# STM32F103ZET7 register map
File version: 1.0
Registers are 32-bit, access not given, reset 0x0 unless marked. A register's access mark holds for its fields unless they carry their own. Offsets are from the block's base; [hi:lo] are bit positions; {n}, {i} and the like mark numbered series; 'fields as' and 'values as' point back to an identical list.

## EXTI
Base 0x40010400
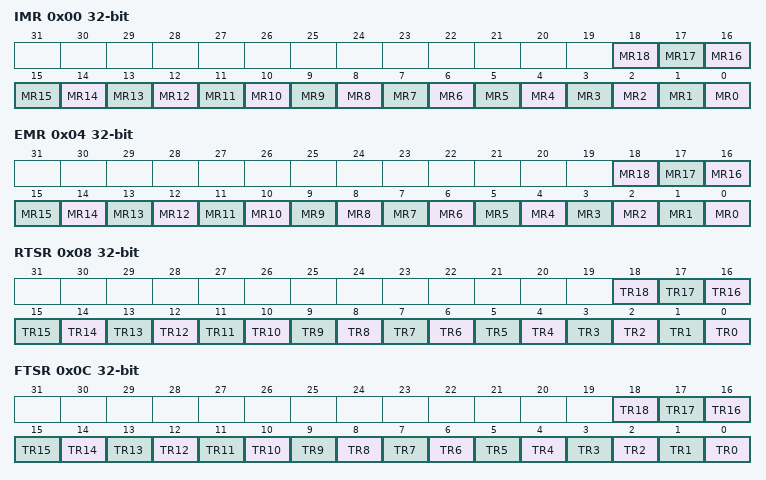
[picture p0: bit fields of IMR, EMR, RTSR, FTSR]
0x00 IMR
  [n] MR{n} (n=0..18)
0x04 EMR
  [n] MR{n} (n=0..18)
0x08 RTSR
  [n] TR{n} (n=0..18)
0x0C FTSR
  [n] TR{n} (n=0..18)
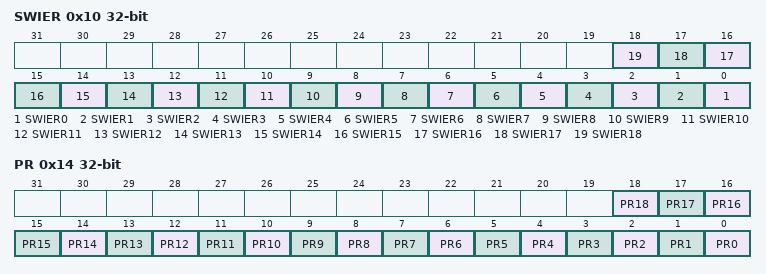
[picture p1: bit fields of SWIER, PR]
0x10 SWIER
  [n] SWIER{n} (n=0..18)
0x14 PR
  [n] PR{n} (n=0..18)

## GPIOA
Base 0x40010800
Same registers: GPIOB 0x40010C00, GPIOC 0x40011000, GPIOD 0x40011400, GPIOE 0x40011800, GPIOF 0x40011C00, GPIOG 0x40012000
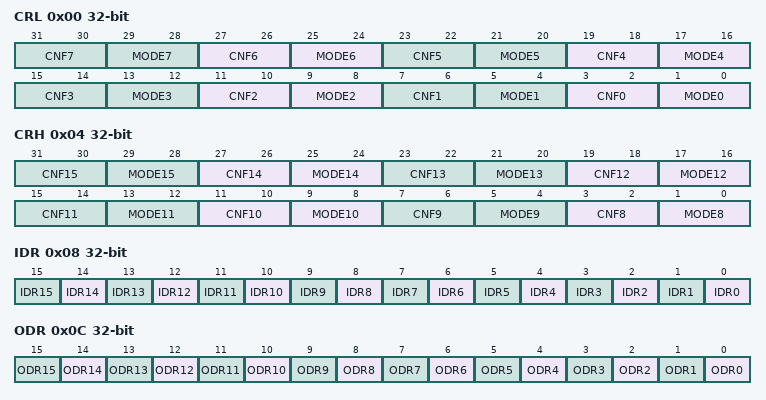
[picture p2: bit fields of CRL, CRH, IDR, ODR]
0x00 CRL
  [4n+3:4n+2] CNF{n} (n=0..7), [4n+1:4n] MODE{n} (n=0..7)
0x04 CRH
  [4n-29:4n-30] CNF{n} (n=8..15), [4n-31:4n-32] MODE{n} (n=8..15)
0x08 IDR
  [n] IDR{n} (n=0..15)
0x0C ODR
  [n] ODR{n} (n=0..15)
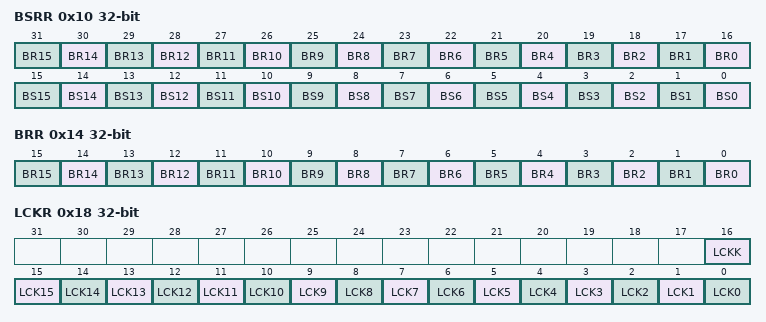
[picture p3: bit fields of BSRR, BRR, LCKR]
0x10 BSRR
  [n+16] BR{n} (n=0..15), [n] BS{n} (n=0..15)
0x14 BRR
  [n] BR{n} (n=0..15)
0x18 LCKR
  [16] LCKK, [n] LCK{n} (n=0..15)

## ADC1
Base 0x40012400
Same registers: ADC3 0x40013C00
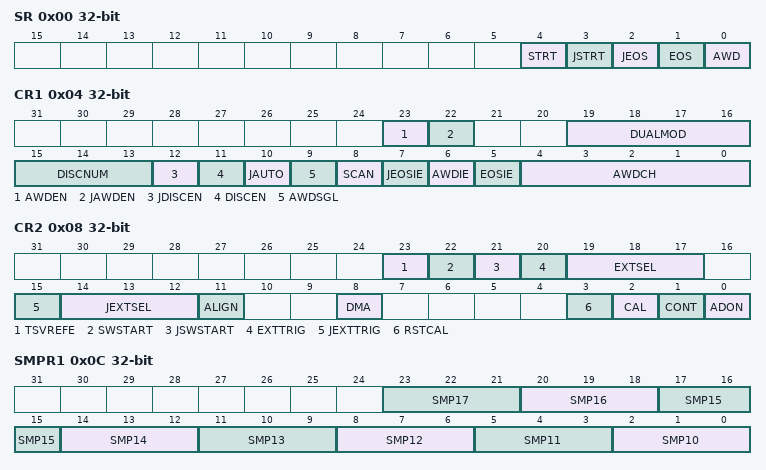
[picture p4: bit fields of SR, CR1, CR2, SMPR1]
0x00 SR
  [4] STRT, [3] JSTRT, [2] JEOS, [1] EOS, [0] AWD
0x04 CR1
  [23] AWDEN, [22] JAWDEN, [19:16] DUALMOD, [15:13] DISCNUM, [12] JDISCEN, [11] DISCEN, [10] JAUTO, [9] AWDSGL, [8] SCAN, [7] JEOSIE, [6] AWDIE, [5] EOSIE, [4:0] AWDCH
0x08 CR2
  [23] TSVREFE, [22] SWSTART, [21] JSWSTART, [20] EXTTRIG, [19:17] EXTSEL, [15] JEXTTRIG, [14:12] JEXTSEL, [11] ALIGN, [8] DMA, [3] RSTCAL, [2] CAL, [1] CONT, [0] ADON
0x0C SMPR1
  [3n-28:3n-30] SMP{n} (n=10..17)
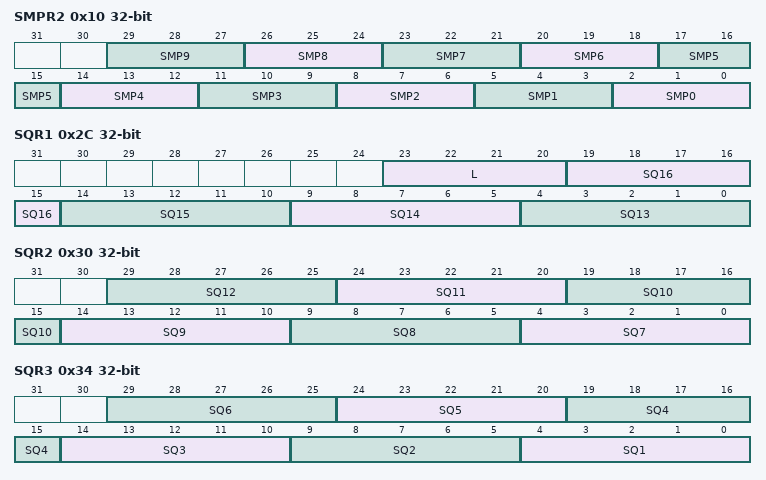
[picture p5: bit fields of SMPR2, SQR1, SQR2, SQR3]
0x10 SMPR2
  [3n+2:3n] SMP{n} (n=0..9)
{0x10+4i} JOFR{i} (i=1..4)
  [11:0] JOFFSET{i}
0x24 HTR
  [11:0] HT
0x28 LTR
  [11:0] LT
0x2C SQR1
  [23:20] L, [5n-61:5n-65] SQ{n} (n=13..16)
0x30 SQR2
  [5n-31:5n-35] SQ{n} (n=7..12)
0x34 SQR3
  [5n-1:5n-5] SQ{n} (n=1..6)
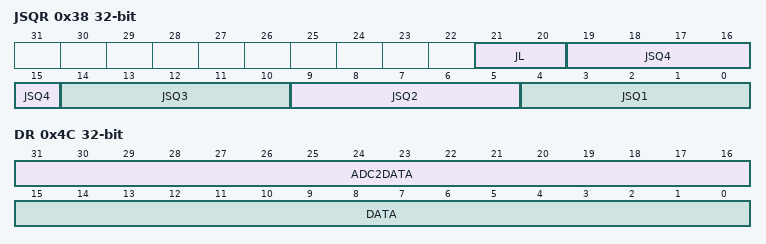
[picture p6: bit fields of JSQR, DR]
0x38 JSQR
  [21:20] JL, [5n-1:5n-5] JSQ{n} (n=1..4)
{0x38+4i} JDR{i} (i=1..4)
  [15:0] JDATA
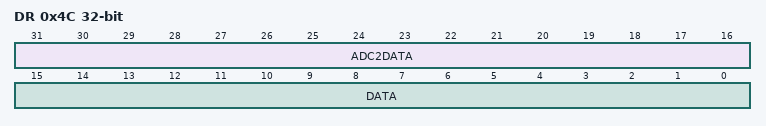
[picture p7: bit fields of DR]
0x4C DR
  [31:16] ADC2DATA, [15:0] DATA

## ADC12_COMMON
Base 0x40012400
Registers as ADC1, without SMPR1, SMPR2, JOFR{n} (n=1..4), HTR, LTR, SQR{n} (n=1..3), JSQR, JDR{n} (n=1..4).

## ADC2
Base 0x40012800
Registers as ADC1; these are added or differ:
0x4C DR
  [31:16] ADC2DATA, [15:0] DATA

## SDIO
Base 0x40018000
0x00 POWER
  [1:0] PWRCTRL
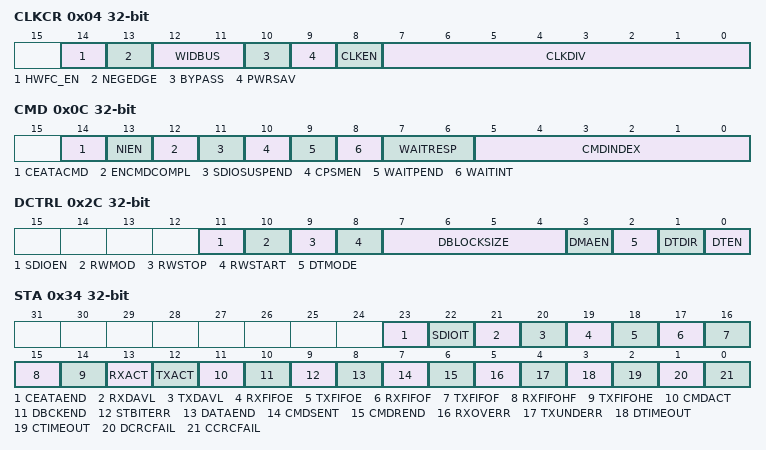
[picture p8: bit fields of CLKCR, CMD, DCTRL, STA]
0x04 CLKCR
  [14] HWFC_EN, [13] NEGEDGE, [12:11] WIDBUS, [10] BYPASS, [9] PWRSAV, [8] CLKEN, [7:0] CLKDIV
0x08 ARG
  [31:0] CMDARG
0x0C CMD
  [14] CEATACMD, [13] NIEN, [12] ENCMDCOMPL, [11] SDIOSUSPEND, [10] CPSMEN, [9] WAITPEND, [8] WAITINT, [7:6] WAITRESP, [5:0] CMDINDEX
0x10 RESPCMD
  [5:0] RESPCMD
{0x10+4i} RESP{i} (i=1..4)
  [31:0] CARDSTATUS{i}
0x24 DTIMER
  [31:0] DATATIME
0x28 DLEN
  [24:0] DATALENGTH
0x2C DCTRL
  [11] SDIOEN, [10] RWMOD, [9] RWSTOP, [8] RWSTART, [7:4] DBLOCKSIZE, [3] DMAEN, [2] DTMODE, [1] DTDIR, [0] DTEN
0x30 DCOUNT
  [24:0] DATACOUNT
0x34 STA
  [23] CEATAEND, [22] SDIOIT, [21] RXDAVL, [20] TXDAVL, [19] RXFIFOE, [18] TXFIFOE, [17] RXFIFOF, [16] TXFIFOF, [15] RXFIFOHF, [14] TXFIFOHE, [13] RXACT, [12] TXACT, [11] CMDACT, [10] DBCKEND, [9] STBITERR, [8] DATAEND, [7] CMDSENT, [6] CMDREND, [5] RXOVERR, [4] TXUNDERR, [3] DTIMEOUT, [2] CTIMEOUT, [1] DCRCFAIL, [0] CCRCFAIL
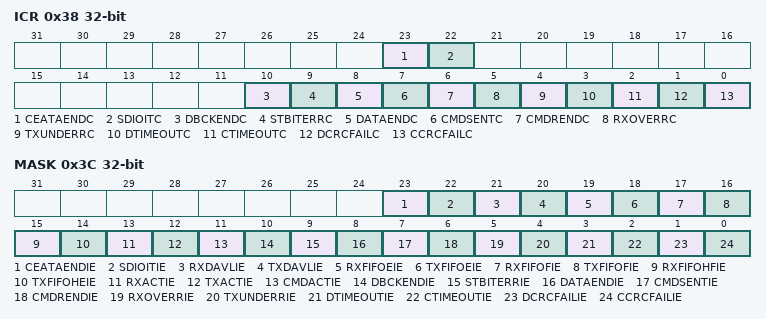
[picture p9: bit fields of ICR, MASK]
0x38 ICR
  [23] CEATAENDC, [22] SDIOITC, [10] DBCKENDC, [9] STBITERRC, [8] DATAENDC, [7] CMDSENTC, [6] CMDRENDC, [5] RXOVERRC, [4] TXUNDERRC, [3] DTIMEOUTC, [2] CTIMEOUTC, [1] DCRCFAILC, [0] CCRCFAILC
0x3C MASK
  [23] CEATAENDIE, [22] SDIOITIE, [21] RXDAVLIE, [20] TXDAVLIE, [19] RXFIFOEIE, [18] TXFIFOEIE, [17] RXFIFOFIE, [16] TXFIFOFIE, [15] RXFIFOHFIE, [14] TXFIFOHEIE, [13] RXACTIE, [12] TXACTIE, [11] CMDACTIE, [10] DBCKENDIE, [9] STBITERRIE, [8] DATAENDIE, [7] CMDSENTIE, [6] CMDRENDIE, [5] RXOVERRIE, [4] TXUNDERRIE, [3] DTIMEOUTIE, [2] CTIMEOUTIE, [1] DCRCFAILIE, [0] CCRCFAILIE
0x48 FIFOCNT
  [23:0] FIFOCOUNT
0x80 FIFO
  [31:0] FIFODATA

## DMA1
Base 0x40020000
Same registers: DMA2 0x40020400
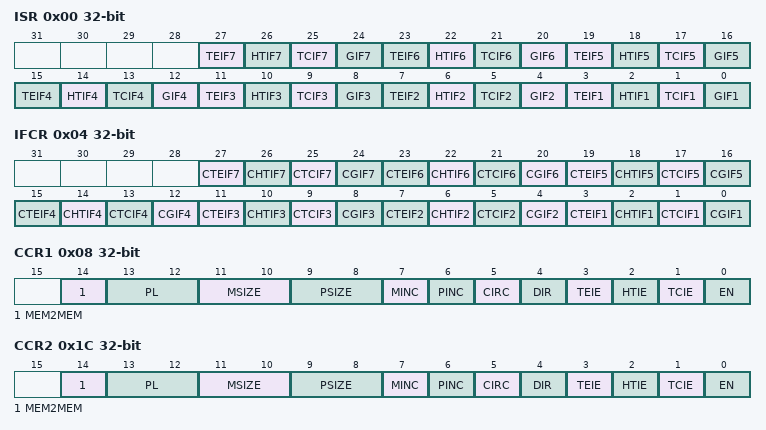
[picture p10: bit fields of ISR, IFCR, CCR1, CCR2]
0x00 ISR
  [4n-1] TEIF{n} (n=1..7), [4n-2] HTIF{n} (n=1..7), [4n-3] TCIF{n} (n=1..7), [4n-4] GIF{n} (n=1..7)
0x04 IFCR
  [4n-1] CTEIF{n} (n=1..7), [4n-2] CHTIF{n} (n=1..7), [4n-3] CTCIF{n} (n=1..7), [4n-4] CGIF{n} (n=1..7)
0x08 CCR1
  [14] MEM2MEM, [13:12] PL, [11:10] MSIZE, [9:8] PSIZE, [7] MINC, [6] PINC, [5] CIRC, [4] DIR, [3] TEIE, [2] HTIE, [1] TCIE, [0] EN
0x0C CNDTR1
  [15:0] NDT
0x10 CPAR1
  [31:0] PA
{0x0+0x14*i} CMAR{i} (i=1..7)
  [31:0] MA
0x1C CCR2
  fields as CCR1
0x20 CNDTR2
  [15:0] NDT
0x24 CPAR2
  [31:0] PA
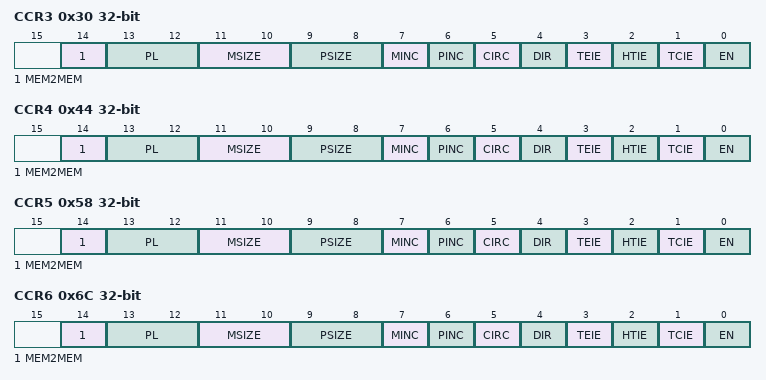
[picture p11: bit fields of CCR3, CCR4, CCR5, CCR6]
0x30 CCR3
  fields as CCR1
0x34 CNDTR3
  [15:0] NDT
0x38 CPAR3
  [31:0] PA
0x44 CCR4
  fields as CCR1
0x48 CNDTR4
  [15:0] NDT
0x4C CPAR4
  [31:0] PA
0x58 CCR5
  fields as CCR1
0x5C CNDTR5
  [15:0] NDT
0x60 CPAR5
  [31:0] PA
0x6C CCR6
  fields as CCR1
0x70 CNDTR6
  [15:0] NDT
0x74 CPAR6
  [31:0] PA
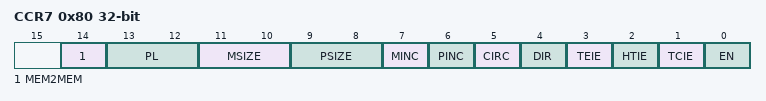
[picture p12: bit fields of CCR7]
0x80 CCR7
  fields as CCR1
0x84 CNDTR7
  [15:0] NDT
0x88 CPAR7
  [31:0] PA
